# STM32L071 register map
File version: 1.3
CPU: CM0+ r0p0, little endian, no MPU, no FPU, 3 interrupt priority bits
Registers are 32-bit, read-write, reset 0x0 unless marked. A register's access mark holds for its fields unless they carry their own. Offsets are from the block's base; [hi:lo] are bit positions; {n}, {i} and the like mark numbered series.

## SYSCFG_COMP — System configuration controller and COMP register
Base 0x40010000
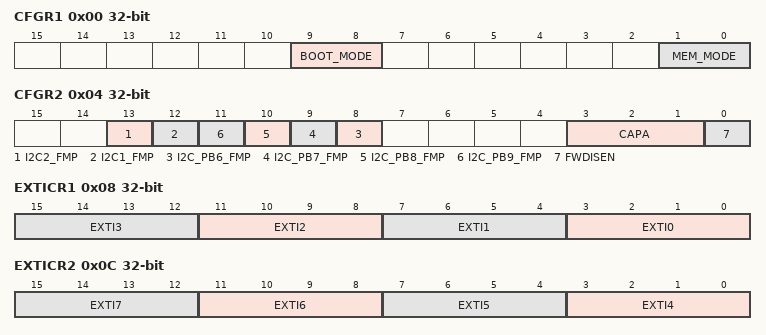
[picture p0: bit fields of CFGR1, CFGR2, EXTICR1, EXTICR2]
0x00 CFGR1 access per field — SYSCFG configuration register 1
  [9:8] BOOT_MODE ro — Boot mode selected by the boot pins status bits
  [1:0] MEM_MODE rw — Memory mapping selection bits
0x04 CFGR2 — SYSCFG configuration register 2
  [13] I2C2_FMP — I2C2 Fm+ drive capability enable bit
  [12] I2C1_FMP — I2C1 Fm+ drive capability enable bit
  [n+2] I2C_PB{n}_FMP (n=6..9) — Fm+ drive capability on PB{n} enable bit
  [3:1] CAPA — Configuration of internal VLCD rail connection to optional external capacitor
  [0] FWDISEN — Firewall disable bit
0x08 EXTICR1 — external interrupt configuration register 1
  [4n+3:4n] EXTI{n} (n=0..3) — EXTI x configuration (x = 0 to 3)
0x0C EXTICR2 — external interrupt configuration register 2
  [4n-13:4n-16] EXTI{n} (n=4..7) — EXTI x configuration (x = 4 to 7)
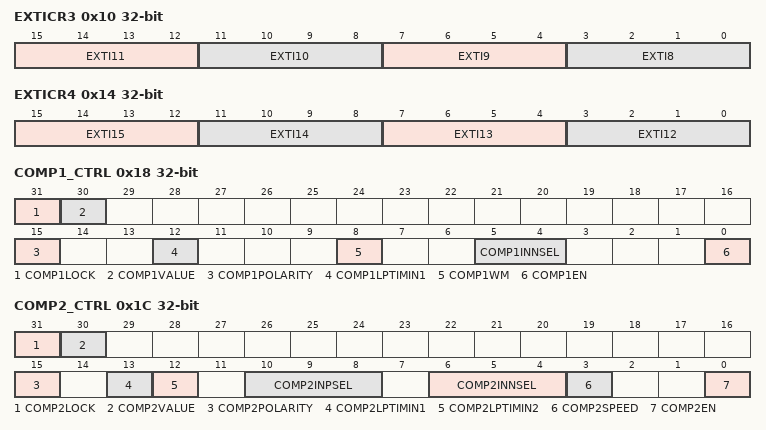
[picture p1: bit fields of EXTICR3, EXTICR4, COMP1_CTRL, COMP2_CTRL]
0x10 EXTICR3 — external interrupt configuration register 3
  [15:12] EXTI11 — EXTI x configuration (x = 8 to 11)
  [11:8] EXTI10
  [7:4] EXTI9 — EXTI x configuration (x = 8 to 11)
  [3:0] EXTI8 — EXTI x configuration (x = 8 to 11)
0x14 EXTICR4 — external interrupt configuration register 4
  [15:12] EXTI15 — EXTI x configuration (x = 12 to 15)
  [11:8] EXTI14
  [7:4] EXTI13
  [3:0] EXTI12
0x18 COMP1_CTRL — Comparator 1 control and status register
  [31] COMP1LOCK — COMP1_CSR register lock bit
  [30] COMP1VALUE — Comparator 1 output status bit
  [15] COMP1POLARITY — Comparator 1 polarity selection bit
  [12] COMP1LPTIMIN1 — Comparator 1 LPTIM input propagation bit
  [8] COMP1WM — Comparator 1 window mode selection bit
  [5:4] COMP1INNSEL — Comparator 1 Input Minus connection configuration bit
  [0] COMP1EN — Comparator 1 enable bit
0x1C COMP2_CTRL — Comparator 2 control and status register
  [31] COMP2LOCK — COMP2_CSR register lock bit
  [30] COMP2VALUE — Comparator 2 output status bit
  [15] COMP2POLARITY — Comparator 2 polarity selection bit
  [13] COMP2LPTIMIN1 — Comparator 2 LPTIM input 1 propagation bit
  [12] COMP2LPTIMIN2 — Comparator 2 LPTIM input 2 propagation bit
  [10:8] COMP2INPSEL — Comparator 2 Input Plus connection configuration bit
  [6:4] COMP2INNSEL — Comparator 2 Input Minus connection configuration bit
  [3] COMP2SPEED — Comparator 2 power mode selection bit
  [0] COMP2EN — Comparator 2 enable bit
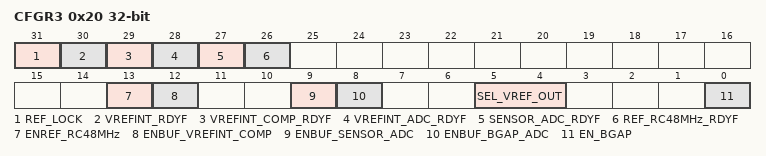
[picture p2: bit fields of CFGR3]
0x20 CFGR3 access per field — SYSCFG configuration register 3
  [31] REF_LOCK wo — REF_CTRL lock bit
  [30] VREFINT_RDYF ro — VREFINT ready flag
  [29] VREFINT_COMP_RDYF ro — VREFINT for comparator ready flag
  [28] VREFINT_ADC_RDYF ro — VREFINT for ADC ready flag
  [27] SENSOR_ADC_RDYF ro — Sensor for ADC ready flag
  [26] REF_RC48MHz_RDYF ro — VREFINT for 48 MHz RC oscillator ready flag
  [13] ENREF_RC48MHz rw — VREFINT reference for 48 MHz RC oscillator enable bit
  [12] ENBUF_VREFINT_COMP rw — VREFINT reference for comparator 2 enable bit
  [9] ENBUF_SENSOR_ADC rw — Sensor reference for ADC enable bit
  [8] ENBUF_BGAP_ADC rw — VREFINT reference for ADC enable bit
  [5:4] SEL_VREF_OUT rw — BGAP_ADC connection bit
  [0] EN_BGAP rw — Vref Enable bit

## SPI1 — Serial peripheral interface
Base 0x40013000
Same registers: SPI2 0x40003800
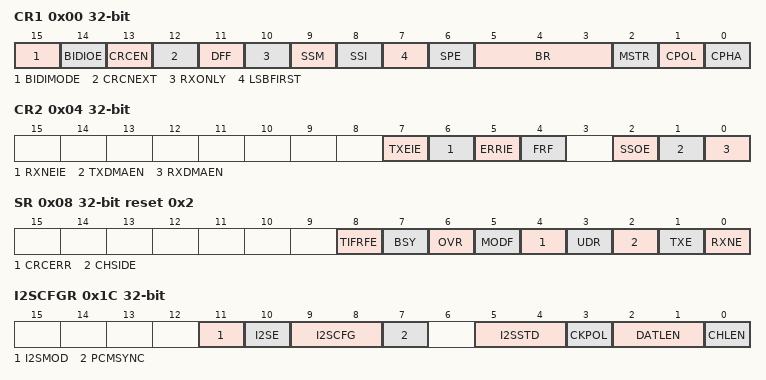
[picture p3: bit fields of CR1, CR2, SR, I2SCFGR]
0x00 CR1 — control register 1
  [15] BIDIMODE — Bidirectional data mode enable
  [14] BIDIOE — Output enable in bidirectional mode
  [13] CRCEN — Hardware CRC calculation enable
  [12] CRCNEXT — CRC transfer next
  [11] DFF — Data frame format
  [10] RXONLY — Receive only
  [9] SSM — Software slave management
  [8] SSI — Internal slave select
  [7] LSBFIRST — Frame format
  [6] SPE — SPI enable
  [5:3] BR — Baud rate control
  [2] MSTR — Master selection
  [1] CPOL — Clock polarity
  [0] CPHA — Clock phase
0x04 CR2 — control register 2
  [7] TXEIE — Tx buffer empty interrupt enable
  [6] RXNEIE — RX buffer not empty interrupt enable
  [5] ERRIE — Error interrupt enable
  [4] FRF — Frame format
  [2] SSOE — SS output enable
  [1] TXDMAEN — Tx buffer DMA enable
  [0] RXDMAEN — Rx buffer DMA enable
0x08 SR access per field reset 0x2 — status register
  [8] TIFRFE ro — TI frame format error
  [7] BSY ro — Busy flag
  [6] OVR ro — Overrun flag
  [5] MODF ro — Mode fault
  [4] CRCERR rw — CRC error flag
  [3] UDR ro — Underrun flag
  [2] CHSIDE ro — Channel side
  [1] TXE ro — Transmit buffer empty
  [0] RXNE ro — Receive buffer not empty
0x0C DR — data register
  [15:0] DR — Data register
0x10 CRCPR reset 0x7 — CRC polynomial register
  [15:0] CRCPOLY
0x14 RXCRCR ro — RX CRC register
  [15:0] RxCRC
0x18 TXCRCR ro — TX CRC register
  [15:0] TxCRC
0x1C I2SCFGR — I2S configuration register
  [11] I2SMOD — I2S mode selection
  [10] I2SE — I2S Enable
  [9:8] I2SCFG — I2S configuration mode
  [7] PCMSYNC — PCM frame synchronization
  [5:4] I2SSTD — I2S standard selection
  [3] CKPOL — Steady state clock polarity
  [2:1] DATLEN — Data length to be transferred
  [0] CHLEN — Channel length (number of bits per audio channel)
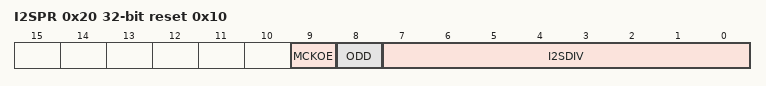
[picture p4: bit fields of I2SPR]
0x20 I2SPR reset 0x10 — I2S prescaler register
  [9] MCKOE — Master clock output enable
  [8] ODD — Odd factor for the prescaler
  [7:0] I2SDIV — I2S Linear prescaler
